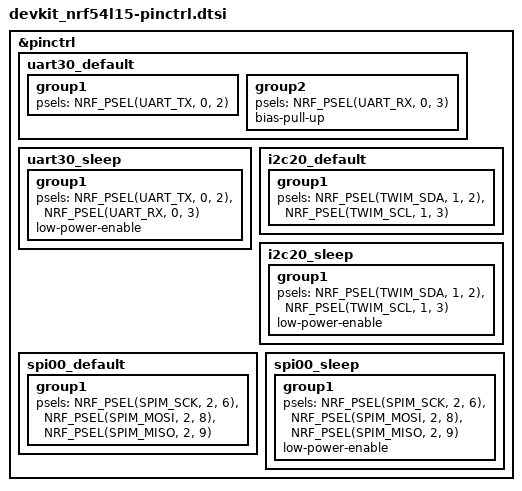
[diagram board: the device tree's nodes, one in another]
/*
 * SPDX-FileCopyrightText: FoBE Studio
 * SPDX-License-Identifier: Apache-2.0
 */

&pinctrl {
	/omit-if-no-ref/ uart30_default: uart30_default {
		group1 {
			psels = <NRF_PSEL(UART_TX, 0, 2)>;
		};

		group2 {
			psels = <NRF_PSEL(UART_RX, 0, 3)>;
			bias-pull-up;
		};
	};

	/omit-if-no-ref/ uart30_sleep: uart30_sleep {
		group1 {
			psels = <NRF_PSEL(UART_TX, 0, 2)>,
				<NRF_PSEL(UART_RX, 0, 3)>;
			low-power-enable;
		};
	};

	/omit-if-no-ref/ i2c20_default: i2c20_default {
		group1 {
			psels = <NRF_PSEL(TWIM_SDA, 1, 2)>,
				<NRF_PSEL(TWIM_SCL, 1, 3)>;
		};
	};

	/omit-if-no-ref/ i2c20_sleep: i2c20_sleep {
		group1 {
			psels = <NRF_PSEL(TWIM_SDA, 1, 2)>,
				<NRF_PSEL(TWIM_SCL, 1, 3)>;
			low-power-enable;
		};
	};

	/omit-if-no-ref/ spi00_default: spi00_default {
		group1 {
			psels = <NRF_PSEL(SPIM_SCK, 2, 6)>,
				<NRF_PSEL(SPIM_MOSI, 2, 8)>,
				<NRF_PSEL(SPIM_MISO, 2, 9)>;
		};
	};

	/omit-if-no-ref/ spi00_sleep: spi00_sleep {
		group1 {
			psels = <NRF_PSEL(SPIM_SCK, 2, 6)>,
				<NRF_PSEL(SPIM_MOSI, 2, 8)>,
				<NRF_PSEL(SPIM_MISO, 2, 9)>;
			low-power-enable;
		};
	};
};
